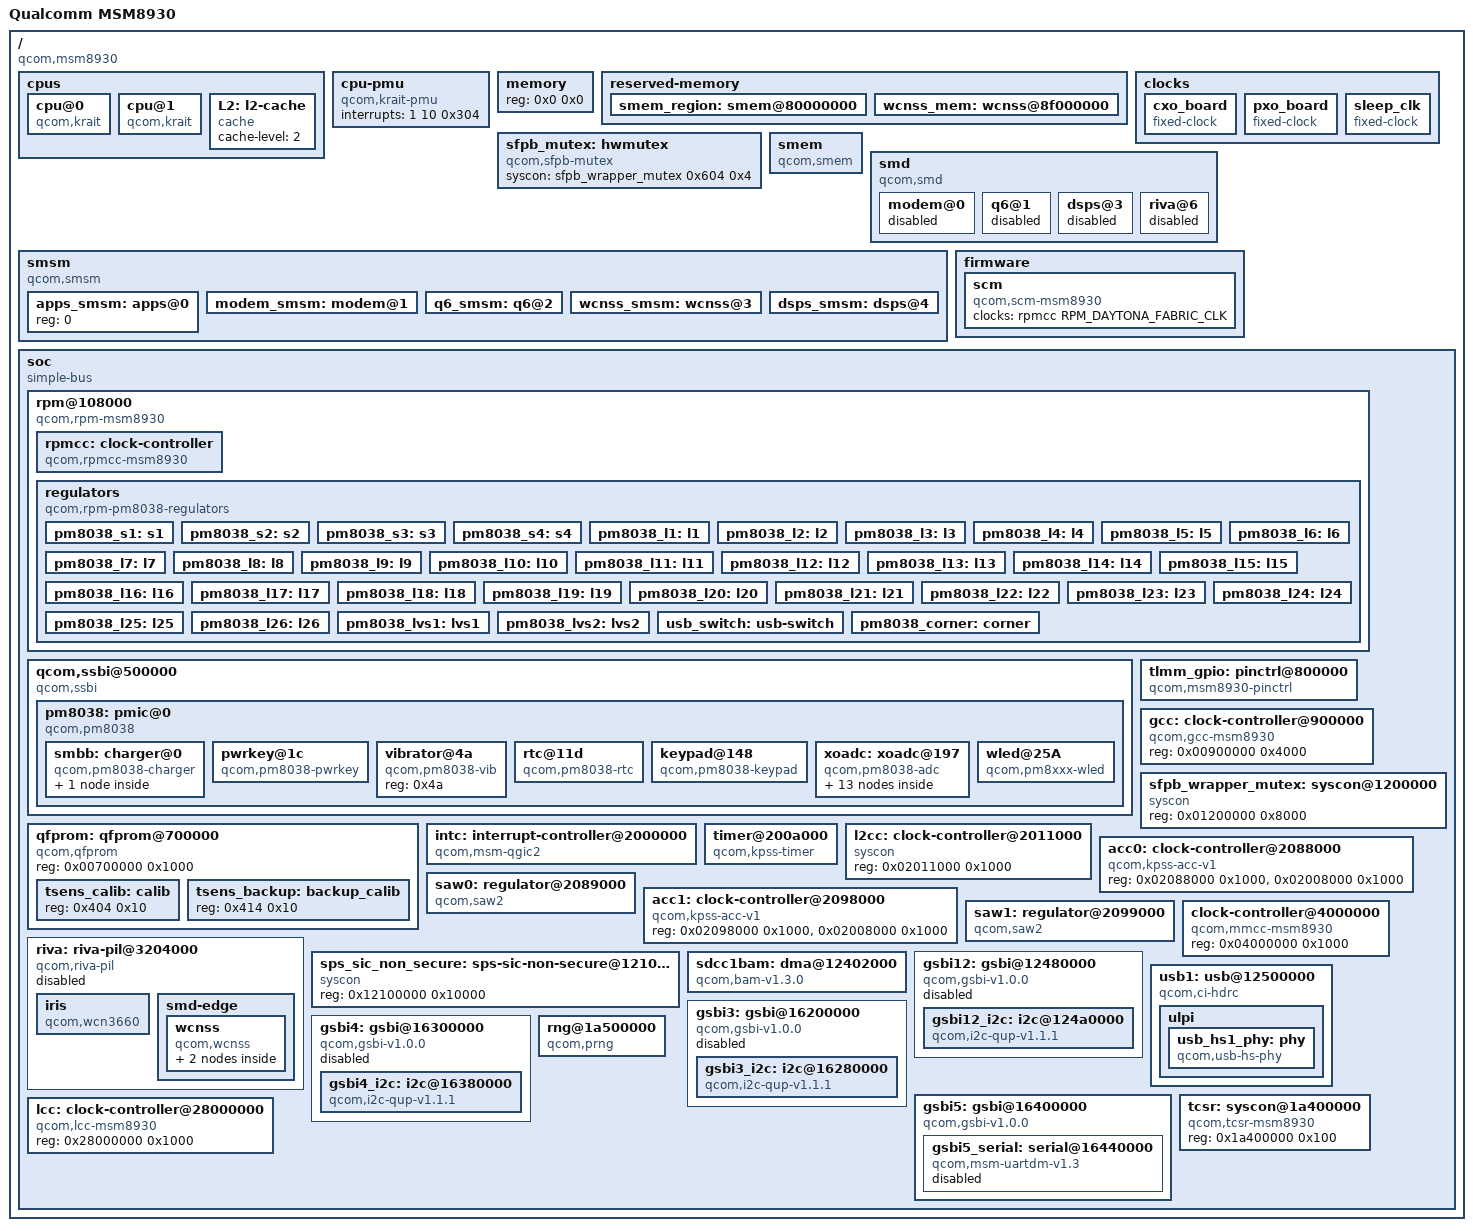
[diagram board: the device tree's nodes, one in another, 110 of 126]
// SPDX-License-Identifier: GPL-2.0
/dts-v1/;

/include/ "skeleton.dtsi"

#include <dt-bindings/interrupt-controller/arm-gic.h>
#include <dt-bindings/interrupt-controller/irq.h>
#include <dt-bindings/clock/qcom,gcc-msm8960.h>
#include <dt-bindings/reset/qcom,gcc-msm8960.h>
#include <dt-bindings/clock/qcom,mmcc-msm8960.h>
#include <dt-bindings/clock/qcom,rpmcc.h>
#include <dt-bindings/mfd/qcom-rpm.h>
#include <dt-bindings/soc/qcom,gsbi.h>
#include <dt-bindings/gpio/gpio.h>

/ {
	#address-cells = <1>;
	#size-cells = <1>;
	model = "Qualcomm MSM8930";
	compatible = "qcom,msm8930";
	interrupt-parent = <&intc>;

	cpus {
		#address-cells = <1>;
		#size-cells = <0>;
		//interrupts = <1 14 0x304>; //from MSM8960
		
		cpu@0 {
			compatible = "qcom,krait";
			enable-method = "qcom,kpss-acc-v1";
			device_type = "cpu";
			reg = <0>;
			next-level-cache = <&L2>;
			qcom,acc = <&acc0>;
			qcom,saw = <&saw0>;
			//cpu-idle-states = <&CPU_SPC>; //from APQ8064
		};

		cpu@1 {
			compatible = "qcom,krait";
			enable-method = "qcom,kpss-acc-v1";
			device_type = "cpu";
			reg = <1>;
			next-level-cache = <&L2>;
			qcom,acc = <&acc1>;
			qcom,saw = <&saw1>;
			//cpu-idle-states = <&CPU_SPC>; //from APQ8064
		};

		L2: l2-cache {
			compatible = "cache";
			cache-level = <2>;
		};

		/*idle-states { //from APQ8064
			CPU_SPC: spc {
				compatible = "qcom,idle-state-spc",
						"arm,idle-state";
				entry-latency-us = <400>;
				exit-latency-us = <900>;
				min-residency-us = <3000>;
			};
		};*/
	};

	cpu-pmu {
		compatible = "qcom,krait-pmu";
		interrupts = <1 10 0x304>;
		//qcom,no-pc-write; //from MSM8960 //Konrad: TODO
	};

	memory {
		device_type = "memory";
		reg = <0x0 0x0>;
	};

	reserved-memory {
		#address-cells = <1>;
		#size-cells = <1>;
		ranges;

		smem_region: smem@80000000 {
			reg = <0x80000000 0x200000>;
			no-map;
		};

		wcnss_mem: wcnss@8f000000 {
			reg = <0x8f000000 0x700000>;
			no-map;
		};
	};

	//thermal-zones {}; //from APQ8064

	clocks {
		cxo_board {
			compatible = "fixed-clock";
			#clock-cells = <0>;
			clock-frequency = <19200000>;
			clock-output-names = "cxo_board"; //from MSM8960
		};

		pxo_board {
			compatible = "fixed-clock";
			#clock-cells = <0>;
			clock-frequency = <27000000>;
			clock-output-names = "pxo_board"; //from MSM8960
		};

		sleep_clk {
			compatible = "fixed-clock";
			#clock-cells = <0>;
			clock-frequency = <32768>;
			clock-output-names = "sleep_clk"; //from MSM8960
		};
	};

	sfpb_mutex: hwmutex {
		compatible = "qcom,sfpb-mutex";
		syscon = <&sfpb_wrapper_mutex 0x604 0x4>;
		#hwlock-cells = <1>;
	};

	smem {
		compatible = "qcom,smem";
		memory-region = <&smem_region>;

		hwlocks = <&sfpb_mutex 3>;
	};

	smd {
		compatible = "qcom,smd";

		modem@0 {
			interrupts = <0 37 IRQ_TYPE_EDGE_RISING>;

			qcom,ipc = <&l2cc 8 3>;
			qcom,smd-edge = <0>;

			status = "disabled";
		};

		q6@1 {
			interrupts = <0 90 IRQ_TYPE_EDGE_RISING>;

			qcom,ipc = <&l2cc 8 15>;
			qcom,smd-edge = <1>;

			status = "disabled";
		};

		dsps@3 {
			interrupts = <0 138 IRQ_TYPE_EDGE_RISING>;

			qcom,ipc = <&sps_sic_non_secure 0x4080 0>;
			qcom,smd-edge = <3>;

			status = "disabled";
		};

		riva@6 {
			interrupts = <0 198 IRQ_TYPE_EDGE_RISING>;

			qcom,ipc = <&l2cc 8 25>;
			qcom,smd-edge = <6>;

			status = "disabled";
		};
	};

	smsm {
		compatible = "qcom,smsm";

		#address-cells = <1>;
		#size-cells = <0>;

		qcom,ipc-1 = <&l2cc 8 4>;
		qcom,ipc-2 = <&l2cc 8 14>;
		qcom,ipc-3 = <&l2cc 8 23>;
		qcom,ipc-4 = <&sps_sic_non_secure 0x4094 0>;

		apps_smsm: apps@0 {
			reg = <0>;
			#qcom,smem-state-cells = <1>;
		};

		modem_smsm: modem@1 {
			reg = <1>;
			interrupts = <0 38 IRQ_TYPE_EDGE_RISING>;

			interrupt-controller;
			#interrupt-cells = <2>;
		};

		q6_smsm: q6@2 {
			reg = <2>;
			interrupts = <0 89 IRQ_TYPE_EDGE_RISING>;

			interrupt-controller;
			#interrupt-cells = <2>;
		};

		wcnss_smsm: wcnss@3 {
			reg = <3>;
			interrupts = <0 204 IRQ_TYPE_EDGE_RISING>;

			interrupt-controller;
			#interrupt-cells = <2>;
		};

		dsps_smsm: dsps@4 {
			reg = <4>;
			interrupts = <0 137 IRQ_TYPE_EDGE_RISING>;

			interrupt-controller;
			#interrupt-cells = <2>;
		};
	};

	firmware {
		scm {
			compatible = "qcom,scm-msm8930";
			clocks = <&rpmcc RPM_DAYTONA_FABRIC_CLK>;
			clock-names = "core";
		};
	};

	soc {
		#address-cells = <1>;
		#size-cells = <1>;
		ranges;
		compatible = "simple-bus";

		rpm@108000 { //MSM8930_RPM_PHYS
			compatible	= "qcom,rpm-msm8930";
			reg			= <0x00108000 0x1000>;
			qcom,ipc	= <&l2cc 0x8 2>;

			interrupts	= <GIC_SPI 19 IRQ_TYPE_EDGE_RISING>, //from MSM8960 //IRQ_TYPE_EDGE_RISING by Konrad
						  <GIC_SPI 21 IRQ_TYPE_EDGE_RISING>, //from MSM8960 //IRQ_TYPE_EDGE_RISING by Konrad
						  <GIC_SPI 22 IRQ_TYPE_EDGE_RISING>; //from MSM8960 //IRQ_TYPE_EDGE_RISING by Konrad
			interrupt-names	= "ack", "err", "wakeup";

			rpmcc: clock-controller {
				compatible	= "qcom,rpmcc-msm8930", "qcom,rpmcc";
				#clock-cells = <1>;
			};

			regulators {
				compatible = "qcom,rpm-pm8038-regulators";

				//from Konrad
				pm8038_s1: s1 {};
				pm8038_s2: s2 {};
				pm8038_s3: s3 {};
				pm8038_s4: s4 {};

				pm8038_l1: l1 {};
				pm8038_l2: l2 {};
				pm8038_l3: l3 {};
				pm8038_l4: l4 {};
				pm8038_l5: l5 {};
				pm8038_l6: l6 {};
				pm8038_l7: l7 {};
				pm8038_l8: l8 {};
				pm8038_l9: l9 {};
				pm8038_l10: l10 {};
				pm8038_l11: l11 {};
				pm8038_l12: l12 {};
				pm8038_l13: l13 {};
				pm8038_l14: l14 {};
				pm8038_l15: l15 {};
				pm8038_l16: l16 {};
				pm8038_l17: l17 {};
				pm8038_l18: l18 {};
				pm8038_l19: l19 {};
				pm8038_l20: l20 {};
				pm8038_l21: l21 {};
				pm8038_l22: l22 {};
				pm8038_l23: l23 {};
				pm8038_l24: l24 {};
				pm8038_l25: l25 {};
				pm8038_l26: l26 {};

				pm8038_lvs1: lvs1 {};
				pm8038_lvs2: lvs2 {};

				usb_switch: usb-switch {};
				pm8038_corner: corner {};
			};
		};
		
		qcom,ssbi@500000 {
			compatible = "qcom,ssbi";
			reg = <0x00500000 0x1000>;
			qcom,controller-type = "pmic-arbiter";

			pm8038: pmic@0 {
				compatible = "qcom,pm8038";
				interrupt-parent = <&tlmm_gpio>;
				interrupts = <104 8>;
				#interrupt-cells = <2>;
				interrupt-controller;
				#address-cells = <1>;
				#size-cells = <0>;

				smbb: charger@0 {
					compatible = "qcom,pm8038-charger";
					reg = <0x0>;

					interrupt-parent = <&pm8038>;
					interrupts =
						<8 1>,  <9 1>,  <10 1>, <11 1>, <12 1>, <13 1>, <14 1>, <15 1>,
						<16 1>, <17 1>, <18 1>, <19 1>, <20 1>, <21 1>, <22 1>, <23 1>,
						<24 1>, <25 1>, <26 1>, <27 1>, <28 1>, <29 1>, <30 1>, <31 1>,
						<40 1>, <41 1>, <42 1>, <43 1>, <44 1>, <45 1>,			<47 1>;
					interrupt-names =
						"vcp", "chg-wdog", "vbat-ov", "usb-uv", "vbatdet-low", "bat-insert", "usb-ov", "usb-valid",
						"chg-trkl", "chg-fast", "loopchange", "chg-state", "chg-fail", "chg-done", "atc-fail", "atc-done",
						"vdd-loop", "course-det-low", "bat-temp-ok", "chg-gone", "bat-temp-cold", "chg-hot", "bat-temp-hot", "bat-remove",
						"dc-uv", "dc-ov", "dc-valid", "psi", "batfet", "vbatdet", "vreg-ov";

					// usb-otg-in-supply = <&pm8941_5vs1>;

					qcom,disable-dc;
				// { "bat-present", smbb_bat_present_handler },

					chg_otg: otg-vbus { };
				};

				pwrkey@1c {
					compatible = "qcom,pm8038-pwrkey";
					reg = <0x1c>;
					interrupt-parent = <&pm8038>;
					interrupts = <50 1>,
								 <51 1>;
					debounce = <15625>;
					pull-up;
				};

				vibrator@4a { //from Konrad
					compatible = "qcom,pm8038-vib";
					reg = <0x4a>;
				};

				/*pm8921_mpps: mpps@50 {
					compatible = "qcom,pm8921-mpp",
						     "qcom,ssbi-mpp";
					reg = <0x50>;
					gpio-controller;
					#gpio-cells = <2>;
					interrupts =
					<128 IRQ_TYPE_NONE>,
					<129 IRQ_TYPE_NONE>,
					<130 IRQ_TYPE_NONE>,
					<131 IRQ_TYPE_NONE>,
					<132 IRQ_TYPE_NONE>,
					<133 IRQ_TYPE_NONE>,
					<134 IRQ_TYPE_NONE>,
					<135 IRQ_TYPE_NONE>,
					<136 IRQ_TYPE_NONE>,
					<137 IRQ_TYPE_NONE>,
					<138 IRQ_TYPE_NONE>,
					<139 IRQ_TYPE_NONE>;
				};*/

				rtc@11d {
					compatible = "qcom,pm8038-rtc";
					interrupt-parent = <&pm8038>;
					interrupts = <39 1>;
					reg = <0x11d>;
					allow-set-time;
				};

				keypad@148 {
					compatible = "qcom,pm8038-keypad";
					reg = <0x148>;
					interrupt-parent = <&pm8038>;
					interrupts = <74 1>,
								 <75 1>;
					debounce = <15>;
					scan-delay = <32>;
					row-hold = <91500>;
				};

				/*pm8038_gpio: gpio@150 {
					compatible = "qcom,pm8038-gpio",
								 "qcom,ssbi-gpio";
					reg = <0x150>;
					interrupt-controller;
					#interrupt-cells = <2>;
					gpio-controller;
					gpio-ranges = <&pm8038_gpio 0 0 44>;
					#gpio-cells = <2>;
				};*/

				xoadc: xoadc@197 { //from Konrad
					compatible = "qcom,pm8038-adc";
					reg = <197>;
					interrupts-extended = <&pm8038 78 IRQ_TYPE_EDGE_RISING>;
					#address-cells = <2>;
					#size-cells = <0>;
					#io-channel-cells = <2>;

					vcoin: adc-channel@00 {
						reg = <0x00 0x00>;
					};
					vbat: adc-channel@01 {
						reg = <0x00 0x01>;
					};
					dcin: adc-channel@02 {
						reg = <0x00 0x02>;
					};
					ichg: adc-channel@03 {
						reg = <0x00 0x03>;
					};
					vph_pwr: adc-channel@04 {
						reg = <0x00 0x04>;
					};
					batt_therm: adc-channel@08 {
						reg = <0x00 0x08>;
					};
					batt_id: adc-channel@09 {
						reg = <0x00 0x09>;
					};
					usb_vbus: adc-channel@0a {
						reg = <0x00 0x0a>;
					};
					die_temp: adc-channel@0b {
						reg = <0x00 0x0b>;
					};
					ref_625mv: adc-channel@0c {
						reg = <0x00 0x0c>;
					};
					ref_1250mv: adc-channel@0d {
						reg = <0x00 0x0d>;
					};
					chg_temp: adc-channel@0e {
						reg = <0x00 0x0e>;
					};
					ref_muxoff: adc-channel@0f {
						reg = <0x00 0x0f>;
					};
				};

				/* using hacked up pm8941 driver */
				wled@25A {
					compatible = "qcom,pm8xxx-wled";
					reg = <0x25A>;
					label = "backlight";

					// dig_mod_gen_en ?
					// op_fdbck ?
					qcom,cs-out;
					qcom,current-limit = <25>;
					qcom,current-boost-limit = <525>;
					qcom,switching-freq = <1600>; // ?
					qcom,ovp = <32>;
					qcom,num-strings = <2>;
				};
			};
		};

		qfprom: qfprom@700000 { //from Konrad
			compatible	= "qcom,qfprom";
			reg		= <0x00700000 0x1000>;
			#address-cells	= <1>;
			#size-cells	= <1>;
			ranges;
			tsens_calib: calib {
				reg = <0x404 0x10>;
			};
			tsens_backup: backup_calib {
				reg = <0x414 0x10>;
			};
		};

		tlmm_gpio: pinctrl@800000 { //MSM8930_TLMM_PHYS
			compatible = "qcom,msm8930-pinctrl";
			gpio-controller;
			gpio-ranges = <&tlmm_gpio 0 0 152>;
			#gpio-cells = <2>;
			interrupts = <0 16 IRQ_TYPE_LEVEL_HIGH>;
			interrupt-controller;
			#interrupt-cells = <2>;
			reg = <0x00800000 0x4000>;
			
			//pinctrl-names = "default"; //from APQ8064
			//pinctrl-0 = <&ps_hold>; //from APQ8064
		};

		gcc: clock-controller@900000 { //MSM8930_CLK_CTL_PHYS
			compatible = "qcom,gcc-msm8930";
			#clock-cells = <1>;
			#reset-cells = <1>;
			reg = <0x00900000 0x4000>;
		};

		sfpb_wrapper_mutex: syscon@1200000 { //from Konrad
			compatible = "syscon";
			reg = <0x01200000 0x8000>;
		};

		intc: interrupt-controller@2000000 { //MSM8930_QGIC_DIST_PHYS
			compatible = "qcom,msm-qgic2";
			interrupt-controller;
			#interrupt-cells = <3>;
			reg = <0x02000000 0x1000>,
				  <0x02002000 0x1000>;
		};

		timer@200a000 { //MSM8930_TMR_PHYS
			compatible = "qcom,kpss-timer",
					 "qcom,kpss-wdt-msm8930", "qcom,msm-timer";
			interrupts = <1 1 0x301>,
						 <1 2 0x301>,
						 <1 3 0x301>;
			reg = <0x0200a000 0x100>;
			clock-frequency = <27000000>,
							  <32768>;
			cpu-offset = <0x80000>;
		};

		l2cc: clock-controller@2011000 { //MSM8930_APCS_GCC_PHYS
			compatible	= "syscon";
			reg		= <0x02011000 0x1000>;
		};

		acc0: clock-controller@2088000 { //MSM8930_ACC0_PHYS
			compatible = "qcom,kpss-acc-v1";
			reg = <0x02088000 0x1000>,
				  <0x02008000 0x1000>;
		};

		saw0: regulator@2089000 { //MSM8930_SAW0_PHYS
			compatible = "qcom,saw2";
			reg = <0x02089000 0x1000>,
				  <0x02009000 0x1000>;
			regulator;
		};

		acc1: clock-controller@2098000 { //MSM8930_ACC1_PHYS
			compatible = "qcom,kpss-acc-v1";
			reg = <0x02098000 0x1000>,
				  <0x02008000 0x1000>;
		};

		saw1: regulator@2099000 { //MSM8930_SAW1_PHYS
			compatible = "qcom,saw2";
			reg = <0x02099000 0x1000>,
				  <0x02009000 0x1000>;
			regulator;
		};

		riva: riva-pil@3204000 {
			compatible = "qcom,riva-pil";

			reg = <0x03200800 0x1000>, <0x03202000 0x2000>, <0x03204000 0x100>;
			reg-names = "ccu", "dxe", "pmu";

			interrupts-extended = <&intc GIC_SPI 199 IRQ_TYPE_EDGE_RISING>,
					      <&wcnss_smsm 6 IRQ_TYPE_EDGE_RISING>;
			interrupt-names = "wdog", "fatal";

			memory-region = <&wcnss_mem>;

			vddcx-supply = <&pm8038_s1>; // ?
			vddmx-supply = <&pm8038_l24>; // ?
			vddpx-supply = <&pm8038_l11>;

			status = "disabled";

			iris {
				compatible = "qcom,wcn3660";

				clocks = <&cxo_board>;
				clock-names = "xo";

				vddxo-supply = <&pm8038_l4>;
				vddrfa-supply = <&pm8038_l1>;
				vddpa-supply = <&pm8038_l10>;
				vdddig-supply = <&pm8038_l2>; // ?
				// vddio l11
			};

			smd-edge {
				interrupts = <GIC_SPI 198 IRQ_TYPE_EDGE_RISING>;

				qcom,ipc = <&l2cc 8 25>;
				qcom,smd-edge = <6>;

				label = "riva";

				wcnss {
					compatible = "qcom,wcnss";
					qcom,smd-channels = "WCNSS_CTRL";

					qcom,mmio = <&riva>;

					bt {
						compatible = "qcom,wcnss-bt";
						local-bd-address = [ 12 34 56 78 9a bc ];
					};

					wifi {
						compatible = "qcom,wcnss-wlan";

						interrupts = <GIC_SPI 203 IRQ_TYPE_LEVEL_HIGH>,
							     <GIC_SPI 202 IRQ_TYPE_LEVEL_HIGH>;
						interrupt-names = "tx", "rx";

						qcom,smem-states = <&apps_smsm 10>, <&apps_smsm 9>;
						qcom,smem-state-names = "tx-enable", "tx-rings-empty";

						local-mac-address = [ 12 34 56 78 9a bd ];
					};
				};
			};
		};

		clock-controller@4000000 { //MSM8930_MMSS_CLK_CTL_PHYS
			compatible = "qcom,mmcc-msm8930";
			reg = <0x04000000 0x1000>;
			#clock-cells = <1>;
			#reset-cells = <1>;
		};

		sps_sic_non_secure: sps-sic-non-secure@12100000 { //from Konrad
			compatible	= "syscon";
			reg		= <0x12100000 0x10000>;
		};

		sdcc1bam:dma@12402000 { //from Konrad
			compatible = "qcom,bam-v1.3.0";
			reg = <0x12402000 0x8000>;
			interrupts = <0 98 IRQ_TYPE_LEVEL_HIGH>;
			clocks = <&gcc SDC1_H_CLK>;
			clock-names = "bam_clk";
			#dma-cells = <1>;
			qcom,ee = <0>;
		};

		gsbi12: gsbi@12480000 {
			status = "disabled";
			compatible = "qcom,gsbi-v1.0.0";
			cell-index = <12>;
			reg = <0x12480000 0x03>; //!! reg size
			clocks = <&gcc GSBI12_H_CLK>;
			clock-names = "iface";
			#address-cells = <1>;
			#size-cells = <1>;
			ranges;

			gsbi12_i2c: i2c@124a0000 {
				compatible = "qcom,i2c-qup-v1.1.1";
				pinctrl-0 = <&i2c12_pins>;
				pinctrl-1 = <&i2c12_pins_sleep>;
				pinctrl-names = "default", "sleep";
				reg = <0x124a0000 0x1000>;
				interrupts = <GIC_SPI 196 IRQ_TYPE_LEVEL_HIGH>;
				clocks = <&gcc GSBI12_QUP_CLK>,
						 <&gcc GSBI12_H_CLK>;
				clock-names = "core", "iface";
				#address-cells = <1>;
				#size-cells = <0>;
			};
		};

		usb1: usb@12500000 { //from Konrad
			compatible = "qcom,ci-hdrc";
			reg = <0x12500000 0x200>,
			      <0x12500200 0x200>;
			interrupts = <GIC_SPI 100 IRQ_TYPE_LEVEL_HIGH>;
			clocks = <&gcc USB_HS1_XCVR_CLK>,
					 <&gcc USB_HS1_H_CLK>;
			clock-names = "core", "iface";
			assigned-clocks = <&gcc USB_HS1_XCVR_CLK>;
			assigned-clock-rates = <60000000>;
			resets = <&gcc USB_HS1_RESET>;
			reset-names = "core";
			phy_type = "ulpi";
			ahb-burst-config = <0>;
			phys = <&usb_hs1_phy>;
			phy-names = "usb-phy";
			#reset-cells = <1>;
			status = "okay";

			ulpi {
				usb_hs1_phy: phy {
					compatible = "qcom,usb-hs-phy";
					clocks = <&sleep_clk>, <&cxo_board>;
					clock-names = "sleep", "ref";
					resets = <&usb1 0>;
					reset-names = "por";
					#phy-cells = <0>;
				};
			};
		};

		//gsbi@16000000 {};

		gsbi3: gsbi@16200000 {
			status = "disabled";
			compatible = "qcom,gsbi-v1.0.0";
			cell-index = <3>;
			reg = <0x16200000 0x100>;
			clocks = <&gcc GSBI3_H_CLK>;
			clock-names = "iface";
			#address-cells = <1>;
			#size-cells = <1>;
			ranges;

			gsbi3_i2c: i2c@16280000 {
				compatible = "qcom,i2c-qup-v1.1.1";
				pinctrl-0 = <&i2c3_pins>;
				pinctrl-1 = <&i2c3_pins_sleep>;
				pinctrl-names = "default", "sleep";
				reg = <0x16280000 0x1000>;
				interrupts = <GIC_SPI 151 IRQ_TYPE_LEVEL_HIGH>;
				clocks = <&gcc GSBI3_QUP_CLK>,
						 <&gcc GSBI3_H_CLK>;
				clock-names = "core", "iface";
				#address-cells = <1>;
				#size-cells = <0>;
			};
		};

		gsbi4: gsbi@16300000 {
			status = "disabled";
			compatible = "qcom,gsbi-v1.0.0";
			cell-index = <4>;
			reg = <0x16300000 0x03>; //!! reg size
			clocks = <&gcc GSBI4_H_CLK>;
			clock-names = "iface";
			#address-cells = <1>;
			#size-cells = <1>;
			ranges;

			gsbi4_i2c: i2c@16380000 {
				compatible = "qcom,i2c-qup-v1.1.1";
				pinctrl-0 = <&i2c4_pins>;
				pinctrl-1 = <&i2c4_pins_sleep>;
				pinctrl-names = "default", "sleep";
				reg = <0x16380000 0x1000>;
				interrupts = <GIC_SPI 153 IRQ_TYPE_LEVEL_HIGH>;
				clocks = <&gcc GSBI4_QUP_CLK>,
						 <&gcc GSBI4_H_CLK>;
				clock-names = "core", "iface";
			};
		};

		gsbi5: gsbi@16400000 {
			compatible = "qcom,gsbi-v1.0.0";
			cell-index = <5>;
			reg = <0x16400000 0x100>;
			clocks = <&gcc GSBI5_H_CLK>;
			clock-names = "iface";
			#address-cells = <1>;
			#size-cells = <1>;
			ranges;

			syscon-tcsr = <&tcsr>;

			gsbi5_serial: serial@16440000 {
				compatible = "qcom,msm-uartdm-v1.3", "qcom,msm-uartdm";
				reg = <0x16440000 0x1000>,
				      <0x16400000 0x1000>;
				interrupts = <0 154 0x0>;
				clocks = <&gcc GSBI5_UART_CLK>,
						 <&gcc GSBI5_H_CLK>;
				clock-names = "core", "iface";
				status = "disabled";
			};
		};

		tcsr: syscon@1a400000 {
			compatible = "qcom,tcsr-msm8930", "syscon";
			reg = <0x1a400000 0x100>;
		};

		rng@1a500000 {
			compatible = "qcom,prng";
			reg = <0x1a500000 0x200>;
			clocks = <&gcc PRNG_CLK>;
			clock-names = "core";
		};

		lcc: clock-controller@28000000 { //MSM8930_LPASS_CLK_CTL_PHYS
			compatible = "qcom,lcc-msm8930";
			reg = <0x28000000 0x1000>;
			#clock-cells = <1>;
			#reset-cells = <1>;
		};

		//vsdcc_fixed: vsdcc-regulator {};
		//amba {};
	};
};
